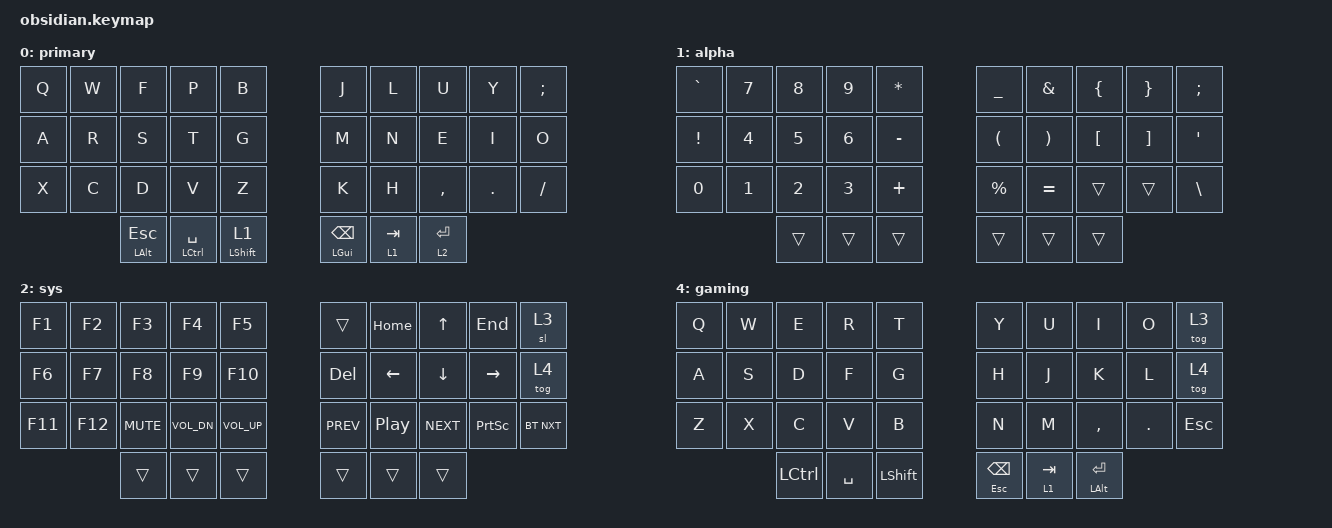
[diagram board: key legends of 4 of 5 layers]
/*
 * Copyright (c) 2020 The ZMK Contributors
 *
 * SPDX-License-Identifier: MIT
 */

#include <behaviors.dtsi>
#include <dt-bindings/zmk/keys.h>
#include <dt-bindings/zmk/bt.h>


&mt {
    tapping-term-ms = <150>;
    quick-tap-ms = <200>;
    flavor = "balanced";
 };
 

 
/* &sk { */
/*      release-after-ms = <2000>; */
/*      quick-release; */
/*  }; */
 
/* Layers */
/ { 

    combos {
        compatible = "zmk,combos";
        combo_bt_clr {
            timeout-ms = <1500>;
            layers = <2>;
            key-positions = <6 8>;
            bindings = <&bt BT_CLR>;
        };
    };
    
    behaviors {
        mlt: mod-layer-tap {
            label = "Mod Layer Tap";
            compatible = "zmk,behavior-hold-tap";
            #binding-cells = <2>;
            flavor = "tap-preferred";
            tapping-term-ms = <150>;
            global-quick-tap;
            bindings = <&kp>, <&sl>;
        };
    };

    keymap {
        compatible = "zmk,keymap";

        primary {
            bindings = <
                   &kp Q    &kp W     &kp F   &kp P    &kp B                 &kp J    &kp L &kp U     &kp Y      &kp SEMI
                   &kp A    &kp R     &kp S   &kp T    &kp G                 &kp M    &kp N &kp E     &kp I      &kp O
                   &kp X    &kp C     &kp D   &kp V    &kp Z                 &kp K    &kp H &kp COMMA &kp PERIOD &kp SLASH

                   &mt LALT ESC &mt LCTRL SPACE &mlt LSHIFT 1                  &mt LGUI BSPC &lt 1 TAB &lt 2 RET

                >;

        };
            
        alpha {
        bindings = <
            &kp GRAVE &kp N7 &kp N8  &kp N9 &kp STAR                       &kp UNDERSCORE &kp AMPERSAND  &kp LBRC       &kp RBRC  &kp SEMI  
            &kp EXCL  &kp N4 &kp N5  &kp N6 &kp MINUS                      &kp LPAR       &kp RPAR       &kp LBKT       &kp RBKT  &kp APOS     
            &kp N0    &kp N1 &kp N2  &kp N3 &kp PLUS                       &kp PERCENT    &kp EQUAL      &trans         &trans    &kp BACKSLASH
                             &trans  &trans &trans                         &trans         &trans         &trans
            >;
        };

        sys {
        bindings = <
            &kp F1  &kp F2  &kp F3     &kp F4       &kp F5                     &trans     &kp HOME   &kp UP     &kp END    &sl 3
            &kp F6  &kp F7  &kp F8     &kp F9       &kp F10                    &kp DEL    &kp LEFT   &kp DOWN   &kp RIGHT  &tog 4
            &kp F11 &kp F12 &kp C_MUTE &kp C_VOL_DN &kp C_VOL_UP               &kp C_PREV &kp C_PP   &kp C_NEXT &kp PSCRN  &bt BT_NXT
                            &trans     &trans       &trans                     &trans     &trans     &trans
            >;
        };
        
        blutooth {
        bindings = <
            &kp F1  &kp F2  &kp F3     &kp F4       &kp F5                     &bt BT_SEL 0     &bt BT_SEL 1   &bt BT_SEL 2   &bt BT_SEL 3   &tog 3
            &kp F6  &kp F7  &kp F8     &kp F9       &kp F10                    &bt BT_SEL 4     &bt BT_SEL 5   &bt BT_SEL 6   &bt BT_SEL 7   &tog 4
            &kp F11 &kp F12 &kp C_MUTE &kp C_VOL_DN &kp C_VOL_UP               &bt BT_CLR       &trans         &trans         &trans
                            &trans     &trans       &trans                     &trans     &trans     &trans
            >;
        };

        gaming {
            bindings = <
                   &kp Q    &kp W     &kp E   &kp R    &kp T                 &kp Y    &kp U &kp I     &kp O      &tog 3
                   &kp A    &kp S     &kp D   &kp F    &kp G                 &kp H    &kp J &kp K     &kp L      &tog 4
                   &kp Z    &kp X     &kp C   &kp V    &kp B                 &kp N    &kp M &kp COMMA &kp PERIOD &kp ESC

                   &kp LCTRL &kp SPACE &kp LSHIFT                          &mt ESC BSPC &lt 1 TAB &mt LALT RET

                >;
        };
    };
    
};
